# nrf52805 register map
Vendor: Nordic Semiconductor; Series: nrf52; File version: 1
CPU: CM4 r0p1, little endian, MPU, no FPU, 3 interrupt priority bits
Registers are 32-bit, read-write, reset 0x0 unless marked. A register's access mark holds for its fields unless they carry their own. Offsets are from the block's base; [hi:lo] are bit positions; lines under a group give offsets from that group; {n}, {i} and the like mark numbered series; 'fields as' and 'values as' point back to an identical list.

## APPROTECT — Only for emulation on devices that support hardened AP-PROTECT.
Base 0x40000000; alternate view of BPROT
0x550 FORCEPROTECT rw-once reset 0xFFFFFFFF — Software force enable APPROTECT mechanism until next reset.
  [7:0] FORCEPROTECT — Write 0x0 to force enable APPROTECT mechanism
    on write: 0=Force (Software force enable APPROTECT mechanism)
0x558 DISABLE — Software disable APPROTECT mechanism
  [7:0] DISABLE
    90=SwDisable (Software disable APPROTECT mechanism)

## P0 — GPIO Port
Base 0x50000000
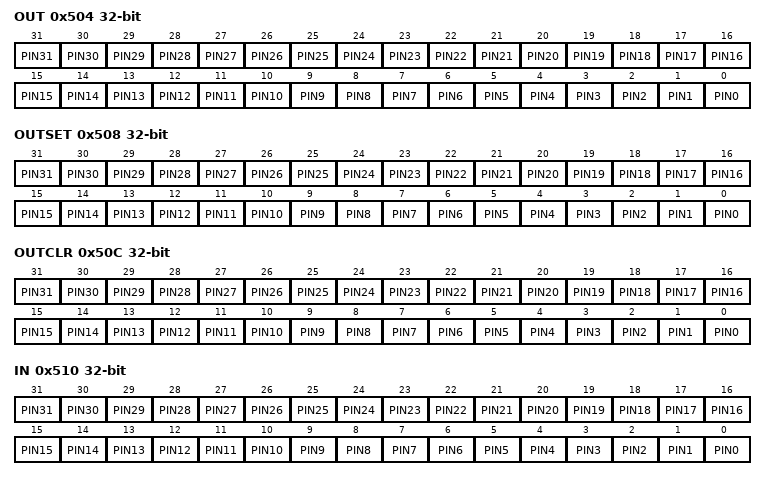
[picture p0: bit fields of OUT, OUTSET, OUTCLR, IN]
0x504 OUT — Write GPIO port
  [all] fields
    0=Low (Pin driver is low); 1=High (Pin driver is high)
  [n] PIN{n} (n=0..31)
0x508 OUTSET write-1-sets — Set individual bits in GPIO port
  [all] fields
    on read: 0=Low (Read: pin driver is low); 1=High (Read: pin driver is high) | on write: 1=Set (Write: a '1' sets the pin high; a '0' has no effect)
  [n] PIN{n} (n=0..31)
0x50C OUTCLR write-1-clears — Clear individual bits in GPIO port
  [all] fields
    on read: 0=Low (Read: pin driver is low); 1=High (Read: pin driver is high) | on write: 1=Clear (Write: a '1' sets the pin low; a '0' has no effect)
  [n] PIN{n} (n=0..31)
0x510 IN ro — Read GPIO port
  [all] fields
    0=Low (Pin input is low); 1=High (Pin input is high)
  [n] PIN{n} (n=0..31)
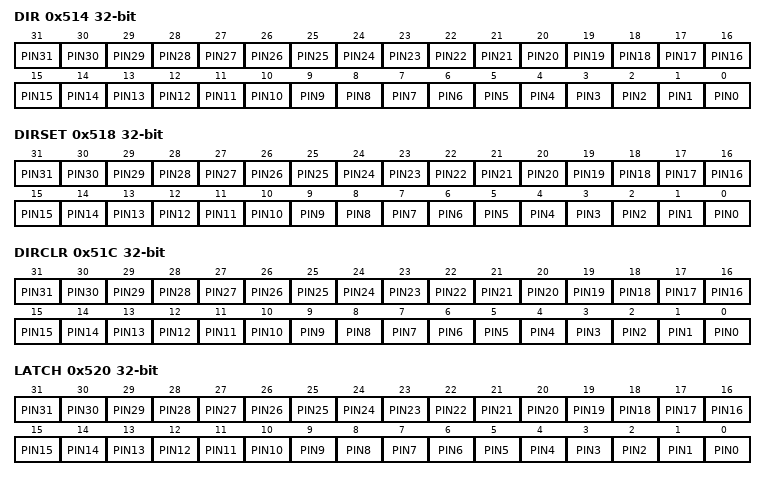
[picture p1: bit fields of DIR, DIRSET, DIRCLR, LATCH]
0x514 DIR — Direction of GPIO pins
  [all] fields
    0=Input (Pin set as input); 1=Output (Pin set as output)
  [n] PIN{n} (n=0..31)
0x518 DIRSET write-1-sets
  [all] fields
    on read: 0=Input (Read: pin set as input); 1=Output (Read: pin set as output) | on write: 1=Set (Write: a '1' sets pin to output; a '0' has no effect)
  [n] PIN{n} (n=0..31) — Set as output pin {n}
0x51C DIRCLR write-1-clears — DIR clear register
  [all] fields
    on read: 0=Input (Read: pin set as input); 1=Output (Read: pin set as output) | on write: 1=Clear (Write: a '1' sets pin to input; a '0' has no effect)
  [n] PIN{n} (n=0..31) — Set as input pin {n}
0x520 LATCH — Latch register indicating what GPIO pins that have met the criteria set in the PIN_CNF[n].SENSE registers
  [all] fields
    0=NotLatched (Criteria has not been met); 1=Latched (Criteria has been met)
  [n] PIN{n} (n=0..31) — Status on whether PIN{n} has met criteria set in PIN_CNF{n}.SENSE register. Write '1' to clear.
0x524 DETECTMODE — Select between default DETECT signal behavior and LDETECT mode
  [0] DETECTMODE
    0=Default (DETECT directly connected to PIN DETECT signals); 1=LDETECT (Use the latched LDETECT behavior)
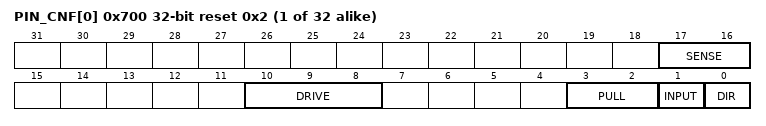
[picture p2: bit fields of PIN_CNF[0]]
{0x700+4i} PIN_CNF[{i}] (i=0..31) reset 0x2 — Description collection: Configuration of GPIO pins
  [17:16] SENSE — Pin sensing mechanism
    0=Disabled; 2=High (Sense for high level); 3=Low (Sense for low level)
  [10:8] DRIVE — Drive configuration
    0=S0S1 (Standard '0', standard '1'); 1=H0S1 (High drive '0', standard '1'); 2=S0H1 (Standard '0', high drive '1'); 3=H0H1 (High drive '0', high 'drive '1''); 4=D0S1 (Disconnect '0' standard '1' (normally used for wired-or connections)); 5=D0H1 (Disconnect '0', high drive '1' (normally used for wired-or connections)); 6=S0D1 (Standard '0'. disconnect '1' (normally used for wired-and connections)); 7=H0D1 (High drive '0', disconnect '1' (normally used for wired-and connections))
  [3:2] PULL — Pull configuration
    0=Disabled (No pull); 1=Pull down on pin; 3=Pull up on pin
  [1] INPUT — Connect or disconnect input buffer
    0=Connect input buffer; 1=Disconnect input buffer
  [0] DIR — Pin direction. Same physical register as DIR register
    0=Input (Configure pin as an input pin); 1=Output (Configure pin as an output pin)

## SPI0 — Serial Peripheral Interface
Base 0x40004000
0x108 EVENTS_READY — TXD byte sent and RXD byte received
  [0] EVENTS_READY
    0=NotGenerated (Event not generated); 1=Generated (Event generated)
0x304 INTENSET — Enable interrupt
  [2] READY — Write '1' to enable interrupt for event READY
    on read: 0=Disabled (Read: Disabled); 1=Enabled (Read: Enabled) | on write: 1=Set (Enable)
0x308 INTENCLR — Disable interrupt
  [2] READY — Write '1' to disable interrupt for event READY
    on read: 0=Disabled (Read: Disabled); 1=Enabled (Read: Enabled) | on write: 1=Clear (Disable)
0x500 ENABLE — Enable SPI
  [3:0] ENABLE — Enable or disable SPI
    0=Disabled (Disable SPI); 1=Enabled (Enable SPI)
0x508 PSEL group — Unspecified
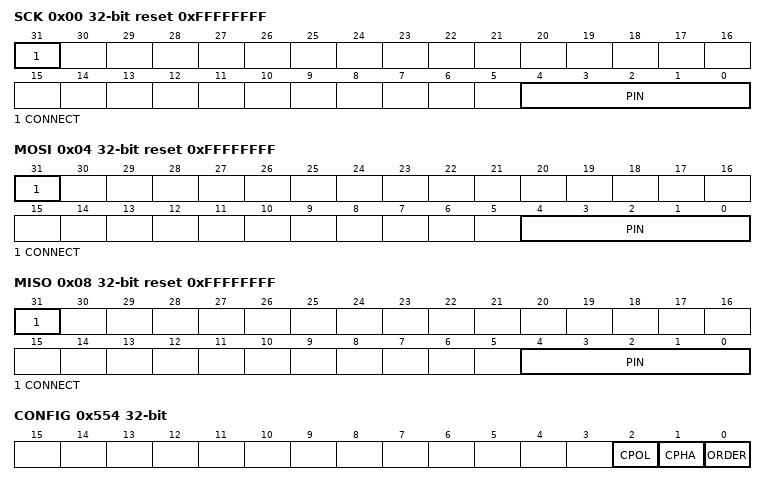
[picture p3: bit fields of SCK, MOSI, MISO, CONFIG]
  0x00 SCK reset 0xFFFFFFFF — Pin select for SCK
    [31] CONNECT — Connection
      1=Disconnected; 0=Connected
    [4:0] PIN — Pin number
  0x04 MOSI reset 0xFFFFFFFF — Pin select for MOSI signal
    fields as PSEL.SCK
  0x08 MISO reset 0xFFFFFFFF — Pin select for MISO signal
    fields as PSEL.SCK
0x518 RXD ro read-has-side-effects
  [7:0] RXD — RX data received. Double buffered
0x51C TXD
  [7:0] TXD — TX data to send. Double buffered.
0x524 FREQUENCY reset 0x4000000 — SPI frequency. Accuracy depends on the HFCLK source selected.
  [31:0] FREQUENCY — SPI master data rate
    0x2000000=K125 (125 kbps); 0x4000000=K250 (250 kbps); 0x8000000=K500 (500 kbps); 0x10000000=M1 (1 Mbps); 0x20000000=M2 (2 Mbps); 0x40000000=M4 (4 Mbps); 0x80000000=M8 (8 Mbps)
0x554 CONFIG — Configuration register
  [2] CPOL — Serial clock (SCK) polarity
    0=ActiveHigh; 1=ActiveLow
  [1] CPHA — Serial clock (SCK) phase
    0=Leading (Sample on leading edge of clock, shift serial data on trailing edge); 1=Trailing (Sample on trailing edge of clock, shift serial data on leading edge)
  [0] ORDER — Bit order
    0=MsbFirst (Most significant bit shifted out first); 1=LsbFirst (Least significant bit shifted out first)
